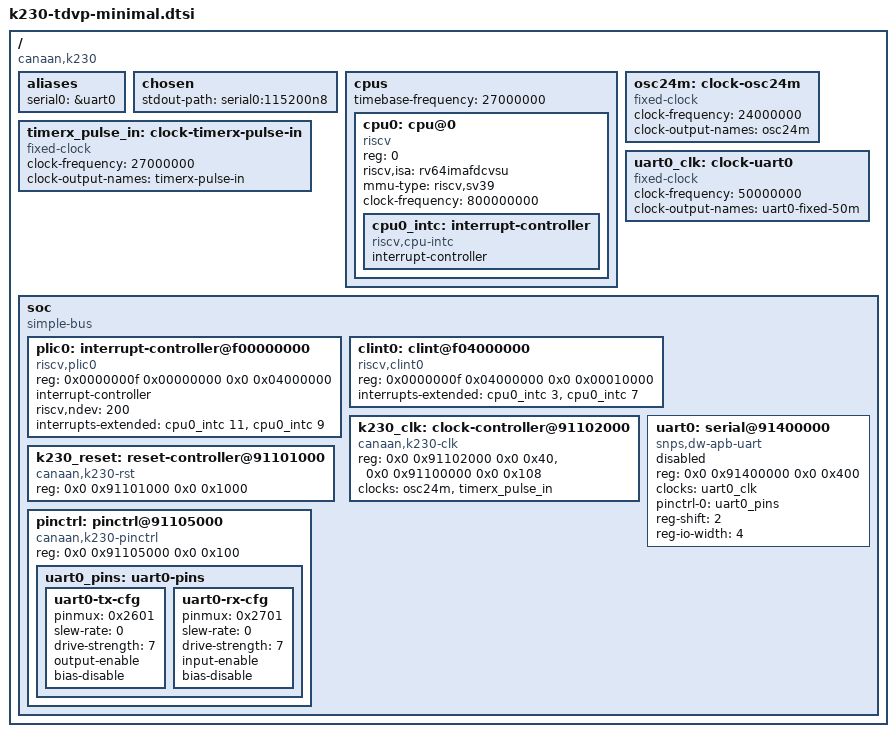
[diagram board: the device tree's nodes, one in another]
// SPDX-License-Identifier: GPL-2.0-only OR BSD-2-Clause

/ {
	compatible = "canaan,k230";
	#address-cells = <2>;
	#size-cells = <2>;

	aliases {
		serial0 = &uart0;
	};

	chosen {
		stdout-path = "serial0:115200n8";
	};

	cpus {
		#address-cells = <1>;
		#size-cells = <0>;
		timebase-frequency = <27000000>;

		cpu0: cpu@0 {
			compatible = "riscv";
			device_type = "cpu";
			reg = <0>;
			status = "okay";
			riscv,isa = "rv64imafdcvsu";
			mmu-type = "riscv,sv39";
			clock-frequency = <800000000>;

			cpu0_intc: interrupt-controller {
				compatible = "riscv,cpu-intc";
				interrupt-controller;
				#interrupt-cells = <1>;
			};
		};
	};

	osc24m: clock-osc24m {
		compatible = "fixed-clock";
		#clock-cells = <0>;
		clock-frequency = <24000000>;
		clock-output-names = "osc24m";
	};

	timerx_pulse_in: clock-timerx-pulse-in {
		compatible = "fixed-clock";
		#clock-cells = <0>;
		clock-frequency = <27000000>;
		clock-output-names = "timerx-pulse-in";
	};

	uart0_clk: clock-uart0 {
		compatible = "fixed-clock";
		#clock-cells = <0>;
		clock-frequency = <50000000>;
		clock-output-names = "uart0-fixed-50m";
	};

	soc {
		compatible = "simple-bus";
		#address-cells = <2>;
		#size-cells = <2>;
		ranges;

		plic0: interrupt-controller@f00000000 {
			compatible = "riscv,plic0";
			reg = <0x0000000f 0x00000000 0x0 0x04000000>;
			interrupt-controller;
			#address-cells = <0>;
			#interrupt-cells = <1>;
			riscv,ndev = <200>;
			interrupts-extended = <&cpu0_intc 11 &cpu0_intc 9>;
		};

		clint0: clint@f04000000 {
			compatible = "riscv,clint0";
			reg = <0x0000000f 0x04000000 0x0 0x00010000>;
			interrupts-extended = <&cpu0_intc 3 &cpu0_intc 7>;
		};

		k230_clk: clock-controller@91102000 {
			compatible = "canaan,k230-clk";
			reg = <0x0 0x91102000 0x0 0x40>,
			      <0x0 0x91100000 0x0 0x108>;
			clocks = <&osc24m>, <&timerx_pulse_in>;
			clock-names = "osc24m", "timer-pulse-in";
			#clock-cells = <1>;
		};

		k230_reset: reset-controller@91101000 {
			compatible = "canaan,k230-rst";
			reg = <0x0 0x91101000 0x0 0x1000>;
			#reset-cells = <1>;
		};

		pinctrl: pinctrl@91105000 {
			compatible = "canaan,k230-pinctrl";
			reg = <0x0 0x91105000 0x0 0x100>;

			uart0_pins: uart0-pins {
				uart0-tx-cfg {
					pinmux = <0x2601>; /* IO38, UART0_TXD */
					slew-rate = <0>;
					drive-strength = <7>;
					output-enable;
					bias-disable;
				};

				uart0-rx-cfg {
					pinmux = <0x2701>; /* IO39, UART0_RXD */
					slew-rate = <0>;
					drive-strength = <7>;
					input-enable;
					bias-disable;
				};
			};
		};

		uart0: serial@91400000 {
			compatible = "snps,dw-apb-uart";
			reg = <0x0 0x91400000 0x0 0x400>;
			clocks = <&uart0_clk>;
			clock-names = "baudclk";
			pinctrl-names = "default";
			pinctrl-0 = <&uart0_pins>;
			reg-shift = <2>;
			reg-io-width = <4>;
			status = "disabled";
		};
	};
};
